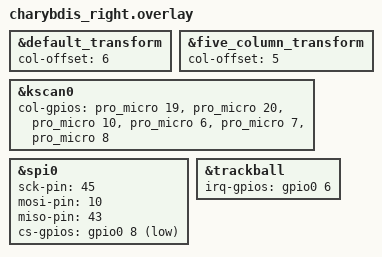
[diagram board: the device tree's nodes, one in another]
/*
 * Copyright (c) 2020 ZMK Contributors
 *
 * SPDX-License-Identifier: MIT
 */
 
#include "charybdis.dtsi"

&default_transform {
	col-offset = <6>;
};

&five_column_transform {
	col-offset = <5>;
};

&kscan0 {
	col-gpios
		= <&pro_micro 19 (GPIO_ACTIVE_HIGH | GPIO_PULL_DOWN)>
		, <&pro_micro 20 (GPIO_ACTIVE_HIGH | GPIO_PULL_DOWN)>
		, <&pro_micro 10 (GPIO_ACTIVE_HIGH | GPIO_PULL_DOWN)>
		, <&pro_micro 6 (GPIO_ACTIVE_HIGH | GPIO_PULL_DOWN)>
		, <&pro_micro 7 (GPIO_ACTIVE_HIGH | GPIO_PULL_DOWN)>
		, <&pro_micro 8 (GPIO_ACTIVE_HIGH | GPIO_PULL_DOWN)>
		;
};

// trackball bus
&spi0 {
	status = "okay"; //okay
	sck-pin = <45>;
	mosi-pin = <10>;
	miso-pin = <43>; // same as mosi (3-wire spi)
	cs-gpios = <&gpio0 8 GPIO_ACTIVE_LOW>;
};

&trackball {
	status = "okay"; //okay
	irq-gpios = <&gpio0 6 (GPIO_ACTIVE_HIGH | GPIO_PULL_DOWN)>;
};
